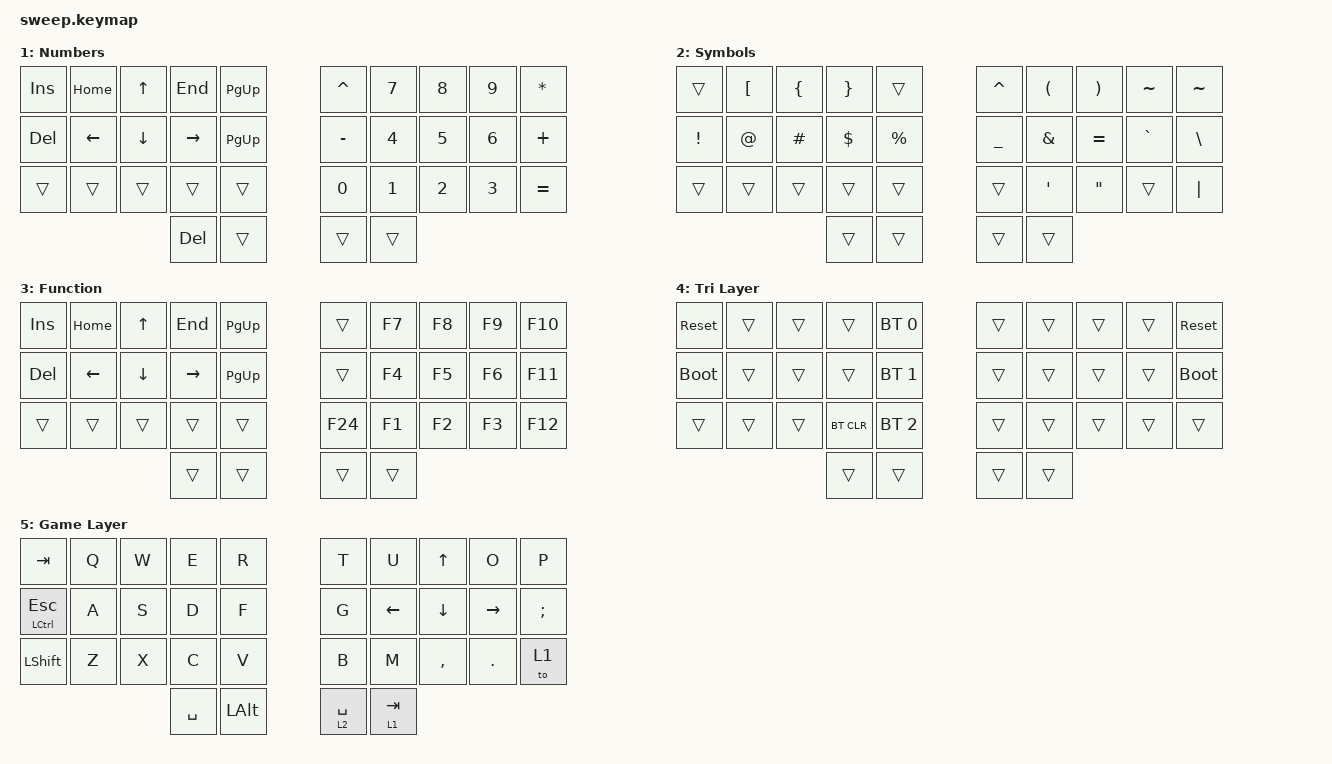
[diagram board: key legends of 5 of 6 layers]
// Copyright (c) 2022 The ZMK Contributors
// SPDX-License-Identifier: MIT

#include <behaviors.dtsi>
#include <dt-bindings/zmk/keys.h>
#include <dt-bindings/zmk/bt.h>

// Home row mods macro
#define HRML(k1,k2,k3,k4) &ht LSHFT k1  &ht LCTRL k2  &ht LALT k3  &ht LGUI k4
#define HRMR(k1,k2,k3,k4) &ht RGUI k1  &ht RALT k2  &ht RCTRL k3  &ht RSHFT k4

/ {
    combos {
        compatible = "zmk,combos";
        combo_lbkt {
            timeout-ms = <50>;
            require-prior-idle-ms = <200>;
            key-positions = <0 1>;
            bindings = <&kp LBKT>;
        };
        combo_lbrc {
            timeout-ms = <50>;
            require-prior-idle-ms = <200>;
            key-positions = <1 2>;
            bindings = <&kp LBRC>;
        };
        combo_lpar {
            timeout-ms = <50>;
            require-prior-idle-ms = <200>;
            key-positions = <2 3>;
            bindings = <&kp LPAR>;
        };
        combo_rbkt {
            timeout-ms = <50>;
            require-prior-idle-ms = <200>;
            key-positions = <8 9>;
            bindings = <&kp RBKT>;
        };
        combo_rbrc {
            timeout-ms = <50>;
            require-prior-idle-ms = <200>;
            key-positions = <7 8>;
            bindings = <&kp RBRC>;
        };
        combo_rpar {
            timeout-ms = <50>;
            require-prior-idle-ms = <200>;
            key-positions = <6 7>;
            bindings = <&kp RPAR>;
        };
        combo_enter {
            timeout-ms = <50>;
            require-prior-idle-ms = <0>;
            key-positions = <26 27>;
            bindings = <&kp ENTER>;
        };
        combo_esc {
            timeout-ms = <50>;
            require-prior-idle-ms = <0>;
            key-positions = <22 23>;
            bindings = <&kp ESC>;
        };
        combo_caps_word {
            timeout-ms = <50>;
            require-prior-idle-ms = <200>;
            key-positions = <10 19>;
	    layers = <0>;
            bindings = <&caps_word>;
        };
        combo_repeat {
            timeout-ms = <50>;
            require-prior-idle-ms = <100>;
            key-positions = <25 26>;
	    layers = <0>;
            bindings = <&key_repeat>;
        };
        combo_game {
            timeout-ms = <50>;
            require-prior-idle-ms = <200>;
            key-positions = <0 10 20>;
	    layers = <0>;
            bindings = <&to 5>;
        };
    };

    behaviors {
        ht: hold_tap {
            compatible = "zmk,behavior-hold-tap";
            #binding-cells = <2>;
            flavor = "balanced";
            tapping-term-ms = <220>;
            quick-tap-ms = <150>;
            require-prior-idle-ms = <100>;
            bindings = <&kp>, <&kp>;
        };
    };

    //conditional_layers {
    //    compatible = "zmk,conditional-layers";
    //    tri_layer {
    //        if-layers = <1 2>;
    //        then-layer = <4>;
    //    };
    //};

    keymap {
        compatible = "zmk,keymap";
        default_layer {
            display-name = "Default Layer";
            bindings = <
        //╭──────────┬──────────┬──────────┬──────────┬──────────╮   ╭──────────┬──────────┬──────────┬──────────┬──────────╮
        //│  Q       │  W       │  E       │  R       │  T       │   │  Y       │  U       │  I       │  O       │  P       │
            &kp Q      &kp W      &kp E      &kp R      &kp T          &kp Y      &kp U      &kp I      &kp O      &kp P
        //├──────────┼──────────┼──────────┼──────────┼──────────┤   ├──────────┼──────────┼──────────┼──────────┼──────────┤
        //│  A       │  S       │  D       │  F       │  G       │   │  H       │  J       │  K       │  L       │ ; :      │
            HRML(A,        S,         D,         F)     &kp G          &kp H      HRMR(J,        K,         L,        SEMI)
        //├──────────┼──────────┼──────────┼──────────┼──────────┤   ├──────────┼──────────┼──────────┼──────────┼──────────┤
        //│  Z       │  X       │  C       │  V       │  B       │   │  N       │  M       │ , <      │ . >      │ / ?      │
            &kp Z      &kp X      &kp C      &kp V      &kp B          &kp N      &kp M      &kp COMMA  &kp DOT    &kp FSLH
        //╰──────────┴──────────┴──────────┼──────────┼──────────┤   ├──────────┼──────────┼──────────┴──────────┴──────────╯
                                            &lt 3 BSPC   &kp ESC      &lt 2 SPACE &lt 1 TAB
        //                                 ╰──────────┴──────────╯   ╰──────────┴──────────╯
            >;
        };

        number_layer {
            display-name = "Numbers";
            bindings = <
        //╭──────────┬──────────┬──────────┬──────────┬──────────╮   ╭──────────┬──────────┬──────────┬──────────┬──────────╮
        //│ INSERT   │          │          │          │          │   │    ^     │    7     │    8     │    9     │    *     │
            &kp INS    &kp HOME   &kp UP     &kp END   &kp PG_UP       &kp CARET   &kp N7    &kp N8      &kp N9    &kp STAR
        //├──────────┼──────────┼──────────┼──────────┼──────────┤   ├──────────┼──────────┼──────────┼──────────┼──────────┤
        //│ DELETE   │          │          │          │          │   │    -     │    4     │    5     │    6     │    +     │
            &kp DEL    &kp LEFT   &kp DOWN   &kp RIGHT  &kp PG_UP      &kp MINUS   &kp N4     &kp N5     &kp N6    &kp PLUS
        //├──────────┼──────────┼──────────┼──────────┼──────────┤   ├──────────┼──────────┼──────────┼──────────┼──────────┤
        //│          │          │          │          │          │   │    0     │    1     │    2     │    3     │    =     │
           &trans      &trans     &trans     &trans     &trans         &kp N0     &kp N1     &kp N2     &kp N3     &kp EQUAL
        //╰──────────┴──────────┴──────────┼──────────┼──────────┤   ├──────────┼──────────┼──────────┴──────────┴──────────╯
                                             &kp DEL     &trans         &trans     &trans
        //                                 ╰──────────┴──────────╯   ╰──────────┴──────────╯
            >;
        };

        symbol_layer {
            display-name = "Symbols";
            bindings = <
        //╭──────────┬──────────┬──────────┬──────────┬──────────╮   ╭──────────┬──────────┬──────────┬──────────┬──────────╮
        //│          │          │  {       │  }       │          │   │  ^       │  (       │  )       │  ~       │  ~       │
            &trans     &kp LBKT   &kp LBRC   &kp RBRC   &trans         &kp CARET  &kp LPAR   &kp RPAR   &kp TILDE   &kp TILDE
        //├──────────┼──────────┼──────────┼──────────┼──────────┤   ├──────────┼──────────┼──────────┼──────────┼──────────┤
        //│  !       │  @       │  #       │  $       │  %       │   │  _       │  &       │  =       │  `       │  \       │
            &kp EXCL   &kp AT     &kp HASH   &kp DLLR   &kp PRCNT      &kp UNDER  &kp AMPS &kp EQUAL  &kp GRAVE   &kp BSLH
        //├──────────┼──────────┼──────────┼──────────┼──────────┤   ├──────────┼──────────┼──────────┼──────────┼──────────┤
        //│          │          │          │          │          │   │          │          │          │          │ |        │
            &trans     &trans     &trans     &trans     &trans         &trans     &kp APOS   &kp DQT    &trans   &kp PIPE
        //╰──────────┴──────────┴──────────┼──────────┼──────────┤   ├──────────┼──────────┼──────────┴──────────┴──────────╯
                                             &trans     &trans         &trans     &trans
        //                                 ╰──────────┴──────────╯   ╰──────────┴──────────╯
            >;
        };

        function_layer {
            display-name = "Function";
            bindings = <
        //╭──────────┬──────────┬──────────┬──────────┬──────────╮   ╭──────────┬──────────┬──────────┬──────────┬──────────╮
        //│ INSERT   │          │          │          │          │   │    ^     │    7     │    8     │    9     │    10    │
            &kp INS    &kp HOME   &kp UP     &kp END   &kp PG_UP       &trans      &kp F7    &kp F8      &kp F9    &kp F10
        //├──────────┼──────────┼──────────┼──────────┼──────────┤   ├──────────┼──────────┼──────────┼──────────┼──────────┤
        //│ DELETE   │          │          │          │          │   │    -     │    4     │    5     │    6     │    11    │
            &kp DEL    &kp LEFT   &kp DOWN   &kp RIGHT  &kp PG_UP      &trans      &kp F4     &kp F5     &kp F6    &kp F11
        //├──────────┼──────────┼──────────┼──────────┼──────────┤   ├──────────┼──────────┼──────────┼──────────┼──────────┤
        //│ CAPS     │          │          │          │          │   │ compose  │    1     │    2     │    3     │    12    │
            &trans     &trans     &trans     &trans     &trans         &kp F24     &kp F1      &kp F2     &kp F3    &kp F12
        //╰──────────┴──────────┴──────────┼──────────┼──────────┤   ├──────────┼──────────┼──────────┴──────────┴──────────╯
                                             &trans     &trans         &trans     &trans
        //                                 ╰──────────┴──────────╯   ╰──────────┴──────────╯
            >;
        };

        tri_layer {
            display-name = "Tri Layer";
            bindings = <
        //╭──────────┬──────────┬──────────┬──────────┬──────────╮   ╭──────────┬──────────┬──────────┬──────────┬──────────╮
        //│ RESET    │          │          │          │PROFILE 0 │   │          │          │          │          │  RESET   │
           &sys_reset  &trans     &trans     &trans    &bt BT_SEL 0    &trans     &trans     &trans     &trans    &sys_reset
        //├──────────┼──────────┼──────────┼──────────┼──────────┤   ├──────────┼──────────┼──────────┼──────────┼──────────┤
        //│BOOTLOADER│          │          │          │PROFILE 1 │   │          │          │          │          │BOOTLOADER│
          &bootloader  &trans     &trans     &trans    &bt BT_SEL 1    &trans     &trans     &trans     &trans    &bootloader
        //├──────────┼──────────┼──────────┼──────────┼──────────┤   ├──────────┼──────────┼──────────┼──────────┼──────────┤
        //│          │          │          │ CLEAR BT │PROFILE 2 │   │          │          │          │          │          │
            &trans     &trans     &trans    &bt BT_CLR &bt BT_SEL 2    &trans     &trans     &trans     &trans     &trans
        //╰──────────┴──────────┴──────────┼──────────┼──────────┤   ├──────────┼──────────┼──────────┴──────────┴──────────╯
                                             &trans     &trans         &trans     &trans
        //                                 ╰──────────┴──────────╯   ╰──────────┴──────────╯
            >;
        };

        game_layer {
            display-name = "Game Layer";
            bindings = <
        //╭──────────┬──────────┬──────────┬──────────┬──────────╮   ╭──────────┬──────────┬──────────┬──────────┬──────────╮
        //│          │  Q       │  W       │  E       │  R       │   │  T       │  U       │  I       │  O       │  P       │
            &kp TAB    &kp Q      &kp W      &kp E      &kp R          &kp T      &kp U      &kp UP      &kp O      &kp P
        //├──────────┼──────────┼──────────┼──────────┼──────────┤   ├──────────┼──────────┼──────────┼──────────┼──────────┤
        //│          │  A       │  S       │  D       │  F       │   │  G       │  J       │  K       │  L       │ ; :      │
          &ht LCTRL ESC &kp A      &kp S      &kp D      &kp  F         &kp G     &kp LEFT   &kp DOWN   &kp RIGHT  &kp SEMI
        //├──────────┼──────────┼──────────┼──────────┼──────────┤   ├──────────┼──────────┼──────────┼──────────┼──────────┤
        //│          │  Z       │  X       │  C       │  V       │   │  B       │  M       │ , <      │ . >      │ / ?      │
           &kp LSHIFT  &kp Z      &kp X      &kp C      &kp V          &kp B      &kp M      &kp COMMA  &kp DOT    &to 1
        //╰──────────┴──────────┴──────────┼──────────┼──────────┤   ├──────────┼──────────┼──────────┴──────────┴──────────╯
                                             &kp SPACE  &kp LALT      &lt 2 SPACE &lt 1 TAB
        //                                 ╰──────────┴──────────╯   ╰──────────┴──────────╯
            >;
        };
    };
};
